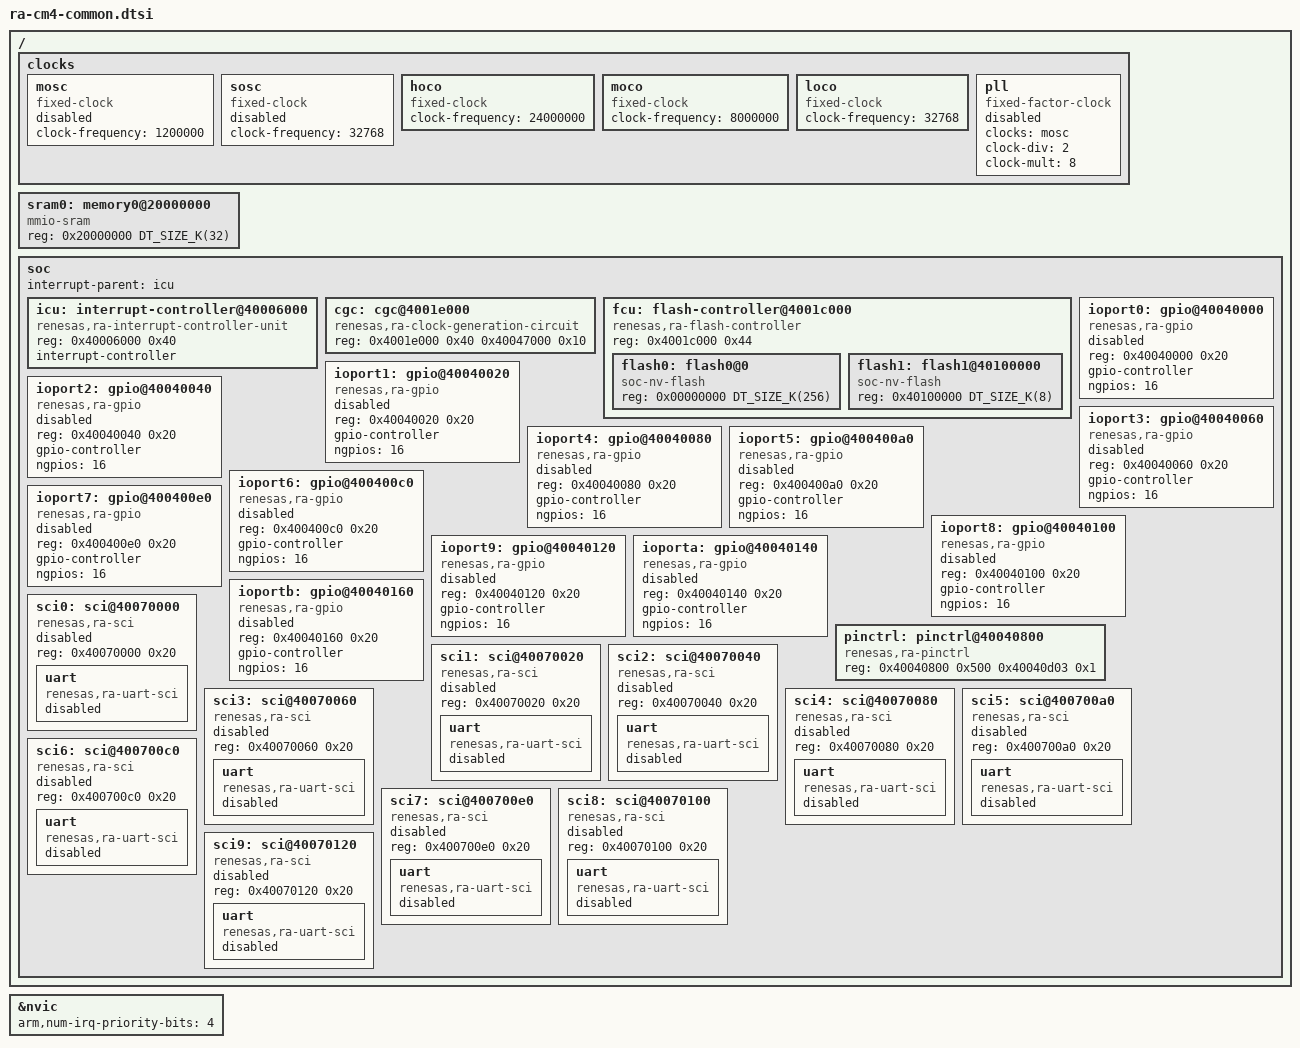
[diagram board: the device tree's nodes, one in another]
/*
 * Copyright (c) 2023 TOKITA Hiroshi <tokita.hiroshi@fujitsu.com>
 *
 * SPDX-License-Identifier: Apache-2.0
 */

#include <mem.h>
#include <freq.h>

/ {
	clocks {
		mosc: mosc {
			compatible = "fixed-clock";
			clock-frequency = <1200000>;
			status = "disabled";
			#clock-cells = <0>;
		};

		sosc: sosc {
			compatible = "fixed-clock";
			clock-frequency = <32768>;
			status = "disabled";
			#clock-cells = <0>;
		};

		hoco: hoco {
			compatible = "fixed-clock";
			clock-frequency = <24000000>;
			status = "okay";
			#clock-cells = <0>;
		};

		moco: moco {
			compatible = "fixed-clock";
			clock-frequency = <8000000>;
			status = "okay";
			#clock-cells = <0>;
		};

		loco: loco {
			compatible = "fixed-clock";
			clock-frequency = <32768>;
			status = "okay";
			#clock-cells = <0>;
		};

		pll: pll {
			compatible = "fixed-factor-clock";
			status = "disabled";
			clocks = <&mosc>;
			clock-div = <2>;
			clock-mult = <8>;
			#clock-cells = <0>;
		};
	};

	sram0: memory0@20000000 {
		compatible = "mmio-sram";
		reg = <0x20000000 DT_SIZE_K(32)>;
	};

	soc {
		interrupt-parent = <&icu>;
		icu: interrupt-controller@40006000 {
			compatible = "renesas,ra-interrupt-controller-unit";
			reg = <0x40006000 0x40>;
			reg-names = "icu";
			interrupt-controller;
			#interrupt-cells = <3>;
		};

		cgc: cgc@4001e000 {
			compatible = "renesas,ra-clock-generation-circuit";
			reg = <0x4001e000 0x40 0x40047000 0x10>;
			reg-names = "system", "mstp";
			#clock-cells = <1>;
		};

		fcu: flash-controller@4001c000 {
			compatible = "renesas,ra-flash-controller";
			reg = <0x4001c000 0x44>;
			reg-names = "fcache";

			#address-cells = <1>;
			#size-cells = <1>;

			flash0: flash0@0 {
				compatible = "soc-nv-flash";
				reg = <0x00000000 DT_SIZE_K(256)>;
			};

			flash1: flash1@40100000 {
				compatible = "soc-nv-flash";
				reg = <0x40100000 DT_SIZE_K(8)>;
			};
		};

		ioport0: gpio@40040000 {
			compatible = "renesas,ra-gpio";
			reg = <0x40040000 0x20>;
			gpio-controller;
			#gpio-cells = <2>;
			ngpios = <16>;
			status = "disabled";
		};

		ioport1: gpio@40040020 {
			compatible = "renesas,ra-gpio";
			reg = <0x40040020 0x20>;
			gpio-controller;
			#gpio-cells = <2>;
			ngpios = <16>;
			status = "disabled";
		};

		ioport2: gpio@40040040 {
			compatible = "renesas,ra-gpio";
			reg = <0x40040040 0x20>;
			gpio-controller;
			#gpio-cells = <2>;
			ngpios = <16>;
			status = "disabled";
		};

		ioport3: gpio@40040060 {
			compatible = "renesas,ra-gpio";
			reg = <0x40040060 0x20>;
			gpio-controller;
			#gpio-cells = <2>;
			ngpios = <16>;
			status = "disabled";
		};

		ioport4: gpio@40040080 {
			compatible = "renesas,ra-gpio";
			reg = <0x40040080 0x20>;
			gpio-controller;
			#gpio-cells = <2>;
			ngpios = <16>;
			status = "disabled";
		};

		ioport5: gpio@400400a0 {
			compatible = "renesas,ra-gpio";
			reg = <0x400400a0 0x20>;
			gpio-controller;
			#gpio-cells = <2>;
			ngpios = <16>;
			status = "disabled";
		};

		ioport6: gpio@400400c0 {
			compatible = "renesas,ra-gpio";
			reg = <0x400400c0 0x20>;
			gpio-controller;
			#gpio-cells = <2>;
			ngpios = <16>;
			status = "disabled";
		};

		ioport7: gpio@400400e0 {
			compatible = "renesas,ra-gpio";
			reg = <0x400400e0 0x20>;
			gpio-controller;
			#gpio-cells = <2>;
			ngpios = <16>;
			status = "disabled";
		};

		ioport8: gpio@40040100 {
			compatible = "renesas,ra-gpio";
			reg = <0x40040100 0x20>;
			gpio-controller;
			#gpio-cells = <2>;
			ngpios = <16>;
			status = "disabled";
		};

		ioport9: gpio@40040120 {
			compatible = "renesas,ra-gpio";
			reg = <0x40040120 0x20>;
			gpio-controller;
			#gpio-cells = <2>;
			ngpios = <16>;
			status = "disabled";
		};

		ioporta: gpio@40040140 {
			compatible = "renesas,ra-gpio";
			reg = <0x40040140 0x20>;
			gpio-controller;
			#gpio-cells = <2>;
			ngpios = <16>;
			status = "disabled";
		};

		ioportb: gpio@40040160 {
			compatible = "renesas,ra-gpio";
			reg = <0x40040160 0x20>;
			gpio-controller;
			#gpio-cells = <2>;
			ngpios = <16>;
			status = "disabled";
		};

		pinctrl: pinctrl@40040800 {
			compatible = "renesas,ra-pinctrl";
			reg = <0x40040800 0x500 0x40040d03 0x1>;
			reg-names = "pfs", "pmisc_pwpr";
			status = "okay";
		};

		sci0: sci@40070000 {
			compatible = "renesas,ra-sci";
			reg = <0x40070000 0x20>;
			#clock-cells = <1>;
			status = "disabled";
			uart {
				compatible = "renesas,ra-uart-sci";
				status = "disabled";
			};
		};

		sci1: sci@40070020 {
			compatible = "renesas,ra-sci";
			reg = <0x40070020 0x20>;
			#clock-cells = <1>;
			status = "disabled";
			uart {
				compatible = "renesas,ra-uart-sci";
				status = "disabled";
			};
		};

		sci2: sci@40070040 {
			compatible = "renesas,ra-sci";
			reg = <0x40070040 0x20>;
			#clock-cells = <1>;
			status = "disabled";
			uart {
				compatible = "renesas,ra-uart-sci";
				status = "disabled";
			};
		};

		sci3: sci@40070060 {
			compatible = "renesas,ra-sci";
			reg = <0x40070060 0x20>;
			#clock-cells = <1>;
			status = "disabled";
			uart {
				compatible = "renesas,ra-uart-sci";
				status = "disabled";
			};
		};

		sci4: sci@40070080 {
			compatible = "renesas,ra-sci";
			reg = <0x40070080 0x20>;
			#clock-cells = <1>;
			status = "disabled";
			uart {
				compatible = "renesas,ra-uart-sci";
				status = "disabled";
			};
		};

		sci5: sci@400700a0 {
			compatible = "renesas,ra-sci";
			reg = <0x400700a0 0x20>;
			#clock-cells = <1>;
			status = "disabled";
			uart {
				compatible = "renesas,ra-uart-sci";
				status = "disabled";
			};
		};

		sci6: sci@400700c0 {
			compatible = "renesas,ra-sci";
			reg = <0x400700c0 0x20>;
			#clock-cells = <1>;
			status = "disabled";
			uart {
				compatible = "renesas,ra-uart-sci";
				status = "disabled";
			};
		};

		sci7: sci@400700e0 {
			compatible = "renesas,ra-sci";
			reg = <0x400700e0 0x20>;
			#clock-cells = <1>;
			status = "disabled";
			uart {
				compatible = "renesas,ra-uart-sci";
				status = "disabled";
			};
		};

		sci8: sci@40070100 {
			compatible = "renesas,ra-sci";
			reg = <0x40070100 0x20>;
			#clock-cells = <1>;
			status = "disabled";
			uart {
				compatible = "renesas,ra-uart-sci";
				status = "disabled";
			};
		};

		sci9: sci@40070120 {
			compatible = "renesas,ra-sci";
			reg = <0x40070120 0x20>;
			#clock-cells = <1>;
			status = "disabled";
			uart {
				compatible = "renesas,ra-uart-sci";
				status = "disabled";
			};
		};
	};
};

&nvic {
	arm,num-irq-priority-bits = <4>;
};
